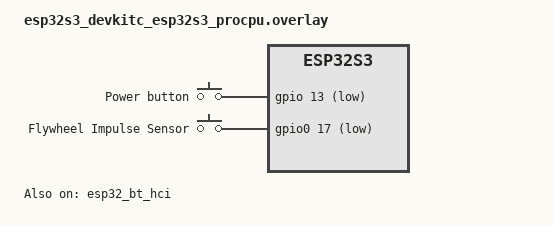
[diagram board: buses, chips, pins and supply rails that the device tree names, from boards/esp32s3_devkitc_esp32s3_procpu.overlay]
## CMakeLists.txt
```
cmake_minimum_required(VERSION 3.22.0)

set(ZEPHYR_EXTRA_MODULES
    ${CMAKE_CURRENT_SOURCE_DIR}/modules/rowing_core/RowingData
    ${CMAKE_CURRENT_SOURCE_DIR}/modules/rowing_core/RowingSettings
    ${CMAKE_CURRENT_SOURCE_DIR}/modules/physics_engine/RowingEngine
    ${CMAKE_CURRENT_SOURCE_DIR}/modules/physics_engine/MovingFlankDetector
    ${CMAKE_CURRENT_SOURCE_DIR}/modules/physics_engine/MovingAverager
    ${CMAKE_CURRENT_SOURCE_DIR}/modules/hardware_driver/GpioTimerService
    ${CMAKE_CURRENT_SOURCE_DIR}/modules/hardware_driver/FakeISR
    ${CMAKE_CURRENT_SOURCE_DIR}/modules/hardware_driver/InputTimerService
    ${CMAKE_CURRENT_SOURCE_DIR}/modules/ble_service/BleManager
    ${CMAKE_CURRENT_SOURCE_DIR}/modules/ble_service/FTMS
    ${CMAKE_CURRENT_SOURCE_DIR}/modules/ble_service/RowerBridge
    ${CMAKE_CURRENT_SOURCE_DIR}/modules/utilities/SystemMonitor
)

find_package(Zephyr REQUIRED HINTS $ENV{ZEPHYR_BASE})

project(ESP32_ORM)

target_sources(app PRIVATE src/main.cpp)

# 2. Add Include Directories Globally
zephyr_include_directories(
    modules/rowing_core/RowingData
    modules/rowing_core/RowingSettings
    modules/physics_engine/RowingEngine
    modules/physics_engine/MovingFlankDetector
    modules/physics_engine/MovingAverager
    modules/hardware_driver/GpioTimerService
    modules/hardware_driver/FakeISR
    modules/hardware_driver/InputTimerService
    modules/ble_service/BleManager
    modules/ble_service/FTMS
    modules/ble_service/RowerBridge
    modules/utilities/SystemMonitor
)
```

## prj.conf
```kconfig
# ==============================================================================
#  OPEN ROWING MONITOR - PRODUCTION CONFIGURATION
#  Version: 1.0.0
# ==============================================================================

# ==============================================================================
#  USER TUNING (Edit these for your specific rower)
# ==============================================================================

# 1. Hardware Setup
CONFIG_ORM_IMPULSES_PER_REV=3

# Standard Flywheel Inertia (x10000). 5000 = 0.5 kg*m^2.
# Check JS profile for your model (e.g., WRX700 is 7200, C2 is ~1000)
CONFIG_ORM_FLYWHEEL_INERTIA_X10000=19

# 2. Calibration
# Standard Concept2 Constant. Higher = fewer meters per stroke.
CONFIG_ORM_MAGIC_CONSTANT_X10000=28000

# Starting/Static Drag Factor (scaled x1M in physics, usually 1500-4500)
CONFIG_ORM_DRAG_FACTOR=45

# 3. Engine Behavior
CONFIG_ORM_AUTO_ADJUST_DRAG_FACTOR=y

# Length of the running average for Drag (strokes)
CONFIG_ORM_DAMPING_CONSTANT_SMOOTING=3

# Noise Filter: Number of samples to confirm Drive vs Recovery
CONFIG_ORM_FLANK_LENGTH=3

# Smoothens power reading. Higher smoother Lower more responsive
CONFIG_ORM_SMOOTHING=3

# 4. Timing Limits (Seconds x10000)
# Min pulse time (0.0050s). Increase if you get double-triggering noise.
CONFIG_ORM_MIN_TIME_BETWEEN_IMPULSE_X10000=50

# Max pulse time (2.0s). JS default for active rowing.
CONFIG_ORM_MAX_TIME_BETWEEN_IMPULSE_X10000=6667

# Timeout for stop (3.0s)
CONFIG_ORM_MAX_IMPULSE_TIME_BEFORE_PAUSE_X10000=30000

# ==============================================================================
#  ZEPHYR SYSTEM CONFIGURATION
# ==============================================================================

# Core C++ Support
CONFIG_CPP=y
CONFIG_STD_CPP17=y
CONFIG_GLIBCXX_LIBCPP=y
CONFIG_NEWLIB_LIBC=y
CONFIG_EVENTS=y

# ==============================================================================
#  LOGGING (Production Mode)
# ==============================================================================

CONFIG_LOG=y
CONFIG_LOG_MODE_DEFERRED=y
CONFIG_LOG_BUFFER_SIZE=2048

# Production log levels (change to LOG_LEVEL_INF or LOG_LEVEL_WRN for release)
# 3=INF, 2=WRN, 1=ERR
CONFIG_LOG_DEFAULT_LEVEL=3

# Disable debug logging in production
# CONFIG_ROWING_ENGINE_LOG_LEVEL_INF=y
# CONFIG_GPIO_TIMER_SERVICE_LOG_LEVEL_INF=y
# CONFIG_BLE_MANAGER_LOG_LEVEL_INF=y
# CONFIG_FTMS_LOG_LEVEL_INF=y

# ==============================================================================
#  BLUETOOTH LOW ENERGY
# ==============================================================================

CONFIG_BT=y
CONFIG_BT_PERIPHERAL=y
CONFIG_BT_DEVICE_NAME="Rowing-Monitor"
CONFIG_BT_DEVICE_APPEARANCE=833

# Bluetooth Performance & Buffers
CONFIG_BT_GATT_DYNAMIC_DB=y
CONFIG_BT_L2CAP_TX_MTU=247
CONFIG_BT_BUF_ACL_TX_SIZE=251
CONFIG_BT_L2CAP_TX_BUF_COUNT=20
CONFIG_BT_BUF_ACL_TX_COUNT=20
CONFIG_BT_BUF_EVT_RX_COUNT=25

# Connection Parameters (optimized for rowing apps)
CONFIG_BT_PERIPHERAL_PREF_MIN_INT=24
CONFIG_BT_PERIPHERAL_PREF_MAX_INT=40

# Connectivity Limits
CONFIG_BT_MAX_CONN=2
CONFIG_BT_MAX_PAIRED=2
CONFIG_BT_CONN_CHECK_NULL_BEFORE_CREATE=y

# ==============================================================================
#  MEMORY CONFIGURATION (Production-Optimized)
# ==============================================================================

# Main thread stack
CONFIG_MAIN_STACK_SIZE=12288

# Physics thread stack
CONFIG_GPIO_PHYSICS_THREAD_STACK_SIZE=8192
CONFIG_FAKEISR_PHYSICS_THREAD_STACK_SIZE=8192
CONFIG_INPUT_PHYSICS_THREAD_STACK_SIZE=8192

# Heap size
CONFIG_HEAP_MEM_POOL_SIZE=65536
CONFIG_SYS_HEAP_RUNTIME_STATS=y

# ==============================================================================
#  INPUT SUBSYSTEM (for hardware-debounced GPIO)
# ==============================================================================

CONFIG_INPUT=y
# Process events in dedicated thread
CONFIG_INPUT_MODE_THREAD=y
# Stack for input thread
CONFIG_INPUT_THREAD_STACK_SIZE=2048
# Override the thread priority
CONFIG_INPUT_THREAD_PRIORITY_OVERRIDE=y
# Lower priority than physics (5)
CONFIG_INPUT_THREAD_PRIORITY=4
# Large queue for high-frequency events
CONFIG_INPUT_QUEUE_MAX_MSGS=256

# Optional: Enable for debugging
# CONFIG_INPUT_EVENT_DUMP=y
# CONFIG_INPUT_SHELL=y

# Enable GPIO keys driver (needed for gpio-keys binding)
CONFIG_INPUT_GPIO_KEYS=y

# ==============================================================================
#  PRODUCTION BUILD SETTINGS
# ==============================================================================

# Optimize for size (or CONFIG_SIZE_OPTIMIZATIONS=y for even smaller binary)
CONFIG_SPEED_OPTIMIZATIONS=y

# Disable debugging features in production
CONFIG_DEBUG=n
CONFIG_DEBUG_OPTIMIZATIONS=n
CONFIG_DEBUG_INFO=n

# Thread monitoring (keep lightweight version)
CONFIG_THREAD_NAME=y
CONFIG_THREAD_STACK_INFO=y

# Assert configuration (reduced for production)
CONFIG_ASSERT=y
# Only critical asserts
CONFIG_ASSERT_LEVEL=1

# Disable coredump in production (saves flash space)
CONFIG_DEBUG_COREDUMP=n
```

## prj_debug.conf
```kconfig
# ==============================================================================
#  ORM options
# ==============================================================================
# CONFIG_SYSM_ENABLE_MONITORING=y
# CONFIG_GPIO_ENABLE_PHYSICS_PROFILING=y

# ==============================================================================
#  Debug options
# ==============================================================================
# CONFIG_DEBUG_OPTIMIZATIONS=y
CONFIG_DEBUG_THREAD_INFO=y
CONFIG_DEBUG_COREDUMP_BACKEND_LOGGING=y
CONFIG_DEBUG_COREDUMP_MEMORY_DUMP_MIN=y
CONFIG_DEBUG_INFO=y

# ==============================================================================
#  Stack options
# ==============================================================================
CONFIG_STACK_CANARIES=y
CONFIG_STACK_SENTINEL=y

# ==============================================================================
#  Thread options
# ==============================================================================
CONFIG_THREAD_MONITOR=y
CONFIG_THREAD_NAME=y
CONFIG_THREAD_STACK_INFO=y

# ==============================================================================
#  Log options
# ==============================================================================
CONFIG_LOG_MODE_IMMEDIATE=y
CONFIG_LOG_BUFFER_SIZE=4096

# ==============================================================================
#  Optimization options
# ==============================================================================
# CONFIG_SPEED_OPTIMIZATIONS=n
# CONFIG_SIZE_OPTIMIZATIONS=n
# Breaks the whole code when enabled.
# CONFIG_NO_OPTIMIZATIONS=y

# ==============================================================================
#  Other options
# ==============================================================================
CONFIG_INIT_STACKS=y
CONFIG_EXCEPTION_DEBUG=y
CONFIG_WATCHDOG=y
CONFIG_FAULT_DUMP=2
CONFIG_SYS_HEAP_VALIDATE=y
```

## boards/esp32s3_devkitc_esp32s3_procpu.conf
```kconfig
# ESP32-S3 Specific Hardware Settings

# Floating Point Unit
CONFIG_FPU=y

# Flash SPI Mode (Standard for S3)
CONFIG_ESPTOOLPY_FLASHMODE_DIO=y
CONFIG_ESPTOOLPY_FLASHFREQ_80M=y

# Flash Configuration (16MB chip)
CONFIG_ESPTOOLPY_FLASHSIZE_16MB=y
```

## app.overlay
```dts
#include <zephyr/dt-bindings/gpio/gpio.h>

/ {
    /* 2. Aliases: Giving C++ friendly names to hardware nodes */
    aliases {
        impulse-sensor = &rower_reed_switch;
        storage-partition = &storage_partition;
    };

    /* 3. GPIO Keys: Virtual device for the Sensor */
    gpio_keys {
        compatible = "gpio-keys";

        rower_reed_switch: reed_switch {
            /* GPIO 17, Pull-Up, Active Low */
            gpios = <&gpio0 17 (GPIO_PULL_UP | GPIO_ACTIVE_LOW)>;
            label = "Flywheel Impulse Sensor";
        };
    };
};

/* 16MB flash */
&flash0 {
    reg = <0x0 DT_SIZE_M(16)>;
    /delete-node/ partitions;
    partitions {
        compatible = "fixed-partitions";
        #address-cells = <1>;
        #size-cells = <1>;

        /* 0x00000 - 0x10000: Bootloader (64KB) */
        boot_partition: partition@0 {
            label = "mcuboot";
            reg = <0x00000000 0x00010000>;
            read-only;
        };

        /* 0x10000 - 0x210000: Application (2MB) */
        /* You can make this larger if your code grows */
        slot0_partition: partition@10000 {
            label = "image-0";
            reg = <0x00010000 0x00200000>;
        };

        /* 0x210000 - End: Storage (~13.8MB) */
        /* This is where LittleFS will live */
        storage_partition: partition@210000 {
            label = "storage";
            reg = <0x00210000 0x00DE0000>;
        };
    };
};

&esp32_bt_hci {
    status = "okay";
};
```

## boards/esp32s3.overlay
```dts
/ {
    aliases {
        // We name our sensor "impulse_sensor"
        impulse-sensor = &rower_reed_switch;
    };

    gpio_keys {
        compatible = "gpio-keys";

        rower_reed_switch: reed_switch {
            // GPIO 17, Pull-Up enabled, Active Low (Magnet closes switch -> Low)
            // If your sensor is Active High, change GPIO_ACTIVE_LOW to GPIO_ACTIVE_HIGH
            gpios = <&gpio0 17 (GPIO_PULL_UP | GPIO_ACTIVE_LOW)>;
            label = "Flywheel Impulse Sensor";
        };
    };
};
```

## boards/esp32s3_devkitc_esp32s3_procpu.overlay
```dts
#include <zephyr/dt-bindings/gpio/gpio.h>

/ {
    /* 2. Aliases: Giving C++ friendly names to hardware nodes */
    aliases {
        impulse-sensor = &rower_reed_switch;
        mode-button = &rower_button;
    };

    /* 3. GPIO Keys: Virtual device for the Sensor */
    gpio_keys {
        compatible = "gpio-keys";
        debounce-interval-ms = <5>;

        rower_button: push_button {
            gpios = <&gpio 13 (GPIO_PULL_UP | GPIO_ACTIVE_LOW)>;
            label = "Power button";
        };
        rower_reed_switch: reed_switch {
            /* GPIO 17, Pull-Up, Active Low */
            gpios = <&gpio0 17 (GPIO_PULL_UP | GPIO_ACTIVE_LOW)>;
            label = "Flywheel Impulse Sensor";
        };
    };
};

&esp32_bt_hci {
    status = "okay";
};

/* 16MB flash */
&flash0 {
	reg = <0x0 DT_SIZE_M(16)>;
};

/* 8MB psram */
&psram0 {
	size = <DT_SIZE_M(8)>;
};
```

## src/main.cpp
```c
#include <zephyr/kernel.h>
#include <zephyr/logging/log.h>
#include <zephyr/sys/sys_heap.h>

// Module Headers
#include "RowingSettings.h"
#include "RowingEngine.h"
#include "GpioTimerService.h"
// #include "FakeISR.h"
// #include "InputTimerService.h"
#include "BleManager.h"
#include "FTMS.h"
#include "RowerBridge.h"
#include "version.h"

#ifdef CONFIG_SYSM_ENABLE_MONITORING
#include "SystemMonitor.h"
#endif

LOG_MODULE_REGISTER(main, LOG_LEVEL_INF);

K_EVENT_DEFINE(mainLoopEvent);
#define BLE_CONNECTED_EVENT     BIT(0)
#define BLE_DISCONNECTED_EVENT  BIT(1)

void printStartupBanner() {
    LOG_INF("╔════════════════════════════════════════════╗");
    LOG_INF("║   Open Rowing Monitor - ESP32              ║");
    LOG_INF("║   Version: %s                              ║", ORM_VERSION_STRING);
    LOG_INF("║   Build: %s (%s)                           ║", ORM_BUILD_TYPE, ORM_BUILD_DATE);
    LOG_INF("╚════════════════════════════════════════════╝");
    LOG_INF("");
}

void printSystemInfo() {
    LOG_INF("System Information:");
    #ifdef CONFIG_SYS_HEAP_RUNTIME_STATS
    // Get the system heap (Zephyr's main heap for k_malloc, etc.)
    extern struct sys_heap _system_heap;

    struct sys_memory_stats stats;
    int ret = sys_heap_runtime_stats_get(&_system_heap, &stats);

    if (ret == 0) {
        LOG_INF("  Heap Free: %u bytes", stats.free_bytes);
    } else {
        LOG_WRN("Failed to get heap stats (error %d)", ret);
    }
    #else
    LOG_DBG("Heap runtime stats not enabled (CONFIG_SYS_HEAP_RUNTIME_STATS=n)");
    #endif
    LOG_INF("  Main Stack: %u bytes", CONFIG_MAIN_STACK_SIZE);
    LOG_INF("  Physics Stack: %u bytes", CONFIG_GPIO_PHYSICS_THREAD_STACK_SIZE);
    // LOG_INF("  Physics Stack: %u bytes", CONFIG_INPUT_PHYSICS_THREAD_STACK_SIZE);
    // LOG_INF("  Physics Stack: %u bytes", CONFIG_FAKEISR_PHYSICS_THREAD_STACK_SIZE);
    LOG_INF("");
}

int main(void)
{
    // Print banner
    printStartupBanner();

    // k_event_init(&mainLoopEvent);

    LOG_INF("Initializing hardware...");

    // 1. Settings & Engine
    RowingSettings settings;
    RowingEngine engine(settings);

    // 2. Hardware Timer Service
    GpioTimerService gpioService(engine, settings);
    if (gpioService.init() != 0) {
        LOG_ERR("Failed to initialize GPIO. Check Devicetree alias 'impulse-sensor'");
        return 0;
    }

    // Using ZephyrRTOS Input subsystem
    // InputTimerService inputService(engine);
    // if (inputService.init() != 0) {
    //     LOG_ERR("Failed to initialize GPIO. Check Devicetree alias 'impulse-sensor'");
    //     return 0;
    // }
    // FakeISR fakeisr(engine);

    // 3. BLE Services & Manager
    FTMS ftmsService;
    ftmsService.init();

    BleManager bleManager;
    bleManager.init(&mainLoopEvent);

    // 4. The Bridge
    RowerBridge bridge(engine, ftmsService, bleManager);
    bridge.init();

#ifdef CONFIG_SYSM_ENABLE_MONITORING
    // 5. System Monitoring (Debug builds only)
    SystemMonitor monitor;
    monitor.init();
    monitor.registerThread(k_current_get(), "main_thread");
    monitor.registerThread(gpioService.getPhysicsThread(), "physics_thread");
    // monitor.registerThread(inputService.getPhysicsThread(), "physics_thread");
    LOG_INF("System monitoring enabled (debug build)");
#endif

    // Print system info
    printSystemInfo();

    LOG_INF("✓ All systems operational. Ready to row.");
    LOG_INF("Advertising as: %s", CONFIG_BT_DEVICE_NAME);
    LOG_INF("");

    engine.startSession();
    k_sleep(K_FOREVER);
    // ================================================================
    // Main Loop
    // ================================================================
    while(1) {
        // Outer Loop
        // Block this thread indefinitely until a connection happens
        // This prevents the main thread from polling continously just to check if there is a connection
        // Event group is handled by BLE Manager

        LOG_INF("Waiting for BLE connection.");
        uint32_t connectedEvent = k_event_wait(&mainLoopEvent, BLE_CONNECTED_EVENT, true, K_FOREVER);
        if(connectedEvent & BLE_CONNECTED_EVENT) {
            LOG_INF("=== SESSION STARTED ===");
            gpioService.resume();
            // inputService.resume();
            // fakeisr.start();
            engine.startSession();
        }
        while(1) {
            // Inner Loop
            // Active session, do all the work needed.

            bridge.update();
            // k_msleep(250);

#ifdef CONFIG_SYSM_ENABLE_MONITORING
            // System Monitoring (every 30 seconds, debug builds only)
            monitor.update(30000);
#endif
            uint32_t disconnectedEvent = k_event_wait(&mainLoopEvent, BLE_DISCONNECTED_EVENT, true, K_MSEC(250));
            if(disconnectedEvent & BLE_DISCONNECTED_EVENT) {
            LOG_INF("=== SESSION ENDED ===");
            gpioService.pause();
            // inputService.pause();
            // fakeisr.stop();
            engine.endSession();
            break;
            }
        }
    }

    return 0;
}
```

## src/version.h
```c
#pragma once

// Open Rowing Monitor - ESP32 Version
#define ORM_VERSION_MAJOR 1
#define ORM_VERSION_MINOR 0
#define ORM_VERSION_PATCH 0

#define ORM_VERSION_STRING "1.0.0"
#define ORM_BUILD_DATE __DATE__
#define ORM_BUILD_TIME __TIME__

// Hardware compatibility
#define ORM_HARDWARE_ESP32S3
#define ORM_MIN_FLASH_SIZE_MB 8

// Feature flags
#define ORM_FEATURE_BLE_FTMS
#define ORM_FEATURE_AUTO_DRAG
#define ORM_FEATURE_MULTI_MAGNET

// Build configuration
#ifdef CONFIG_DEBUG
#define ORM_BUILD_TYPE "Debug"
#else
#define ORM_BUILD_TYPE "Release"
#endif
```
